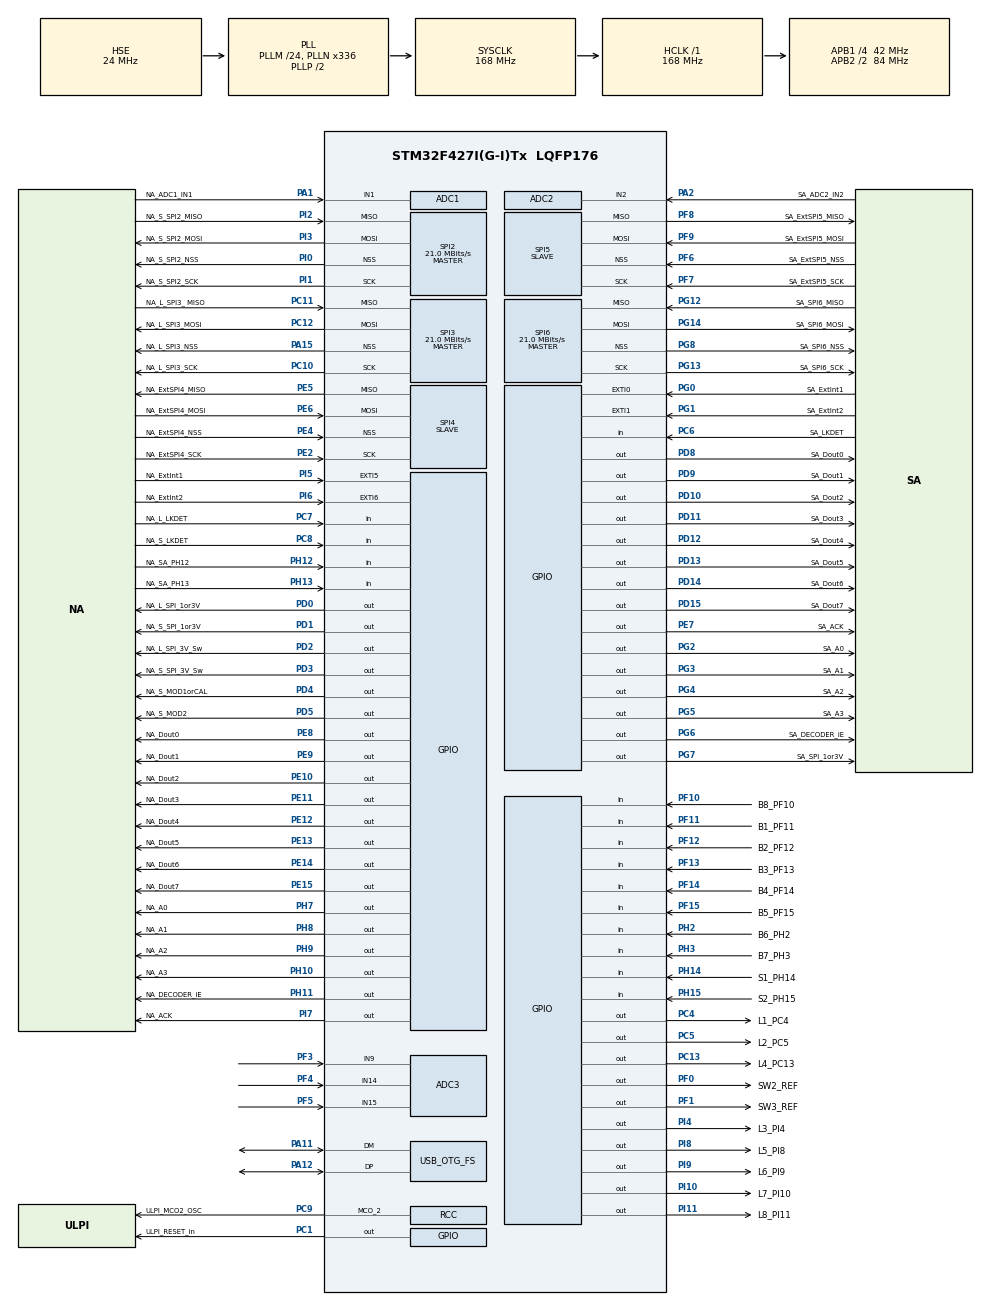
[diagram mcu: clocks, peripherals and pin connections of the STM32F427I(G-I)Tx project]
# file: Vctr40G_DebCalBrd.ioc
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ADC1.Channel-0\#ChannelRegularConversion=ADC_CHANNEL_1
ADC1.ClockPrescaler=ADC_CLOCK_SYNC_PCLK_DIV4
ADC1.NbrOfConversionFlag=1
ADC1.Rank-0\#ChannelRegularConversion=1
ADC1.SamplingTime-0\#ChannelRegularConversion=ADC_SAMPLETIME_3CYCLES
ADC1.master=1
ADC2.Channel-0\#ChannelRegularConversion=ADC_CHANNEL_2
ADC2.ClockPrescaler=ADC_CLOCK_SYNC_PCLK_DIV4
ADC2.NbrOfConversionFlag=1
ADC2.Rank-0\#ChannelRegularConversion=1
ADC2.SamplingTime-0\#ChannelRegularConversion=ADC_SAMPLETIME_3CYCLES
ADC3.Channel-0\#ChannelRegularConversion=ADC_CHANNEL_9
ADC3.ClockPrescaler=ADC_CLOCK_SYNC_PCLK_DIV4
ADC3.NbrOfConversionFlag=1
ADC3.Rank-0\#ChannelRegularConversion=1
ADC3.SamplingTime-0\#ChannelRegularConversion=ADC_SAMPLETIME_3CYCLES
Mcu.Family=STM32F4
Mcu.Name=STM32F427I(G-I)Tx
Mcu.Package=LQFP176
NVIC.EXTI0_IRQn=true\:0\:0\:false\:false\:true\:true\:true\:true
NVIC.EXTI1_IRQn=true\:0\:0\:false\:false\:true\:true\:true\:true
NVIC.EXTI9_5_IRQn=true\:0\:0\:false\:false\:true\:true\:true\:true
NVIC.OTG_FS_IRQn=true\:0\:0\:false\:false\:true\:false\:true\:true
NVIC.PriorityGroup=NVIC_PRIORITYGROUP_4
NVIC.SPI2_IRQn=true\:0\:0\:false\:false\:true\:true\:true\:true
NVIC.SPI3_IRQn=true\:0\:0\:false\:false\:true\:true\:true\:true
NVIC.SPI4_IRQn=true\:0\:0\:false\:false\:true\:true\:true\:true
NVIC.SPI5_IRQn=true\:0\:0\:false\:false\:true\:true\:true\:true
NVIC.SPI6_IRQn=true\:0\:0\:false\:false\:true\:true\:true\:true
NVIC.TIM1_UP_TIM10_IRQn=true\:0\:0\:false\:false\:true\:true\:true\:true
PA0/WKUP.Mode=SYS_WakeUp0
PA0/WKUP.Signal=SYS_WKUP
PA1.GPIO_Label=NA_ADC1_IN1
PA1.Signal=ADCx_IN1
PA11.Mode=Device_Only
PA11.Signal=USB_OTG_FS_DM
PA12.Mode=Device_Only
PA12.Signal=USB_OTG_FS_DP
PA13.Mode=Serial_Wire
PA13.Signal=SYS_JTMS-SWDIO
PA14.Mode=Serial_Wire
PA14.Signal=SYS_JTCK-SWCLK
PA15.GPIO_Label=NA_L_SPI3_NSS
PA15.Mode=NSS_Signal_Hard_Output
PA15.Signal=SPI3_NSS
PA2.GPIO_Label=SA_ADC2_IN2
PA2.Signal=ADCx_IN2
PA3.Signal=USB_OTG_HS_ULPI_D0
PA5.Signal=USB_OTG_HS_ULPI_CK
PB0.Signal=USB_OTG_HS_ULPI_D1
PB1.Signal=USB_OTG_HS_ULPI_D2
PB10.Signal=USB_OTG_HS_ULPI_D3
PB11.Signal=USB_OTG_HS_ULPI_D4
PB12.Signal=USB_OTG_HS_ULPI_D5
PB13.Signal=USB_OTG_HS_ULPI_D6
PB3.Signal=SYS_JTDO-SWO
PB4.Signal=SYS_JTRST
PB5.Signal=USB_OTG_HS_ULPI_D7
PC0.Signal=USB_OTG_HS_ULPI_STP
PC1.GPIO_Label=ULPI_RESET_in
PC1.Signal=GPIO_Output
PC10.GPIO_Label=NA_L_SPI3_SCK
PC10.Mode=Full_Duplex_Master
PC10.Signal=SPI3_SCK
PC11.GPIO_Label=NA_L_SPI3_ MISO
PC11.Mode=Full_Duplex_Master
PC11.Signal=SPI3_MISO
PC12.GPIO_Label=NA_L_SPI3_MOSI
PC12.Mode=Full_Duplex_Master
PC12.Signal=SPI3_MOSI
PC13.GPIO_Label=L4_PC13
PC13.Signal=GPIO_Output
PC14/OSC32_IN.Mode=LSE-External-Oscillator
PC14/OSC32_IN.Signal=RCC_OSC32_IN
PC15/OSC32_OUT.Mode=LSE-External-Oscillator
PC15/OSC32_OUT.Signal=RCC_OSC32_OUT
PC2.Signal=USB_OTG_HS_ULPI_DIR
PC3.Signal=USB_OTG_HS_ULPI_NXT
PC4.GPIO_Label=L1_PC4
PC4.Signal=GPIO_Output
PC5.GPIO_Label=L2_PC5
PC5.Signal=GPIO_Output
PC6.GPIO_Label=SA_LKDET
PC6.Signal=GPIO_Input
PC7.GPIO_Label=NA_L_LKDET
PC7.Signal=GPIO_Input
PC8.GPIO_Label=NA_S_LKDET
PC8.Signal=GPIO_Input
PC9.GPIO_Label=ULPI_MCO2_OSC
PC9.GPIO_Speed=GPIO_SPEED_FREQ_VERY_HIGH
PC9.Mode=Clock-out-2
PC9.Signal=RCC_MCO_2
PD0.GPIO_Label=NA_L_SPI_1or3V
PD0.GPIO_Speed=GPIO_SPEED_FREQ_VERY_HIGH
PD0.Signal=GPIO_Output
PD1.GPIO_Label=NA_S_SPI_1or3V
PD1.GPIO_Speed=GPIO_SPEED_FREQ_VERY_HIGH
PD1.Signal=GPIO_Output
PD10.GPIO_Label=SA_Dout2
PD10.GPIO_Speed=GPIO_SPEED_FREQ_VERY_HIGH
PD10.Signal=GPIO_Output
PD11.GPIO_Label=SA_Dout3
PD11.GPIO_Speed=GPIO_SPEED_FREQ_VERY_HIGH
PD11.Signal=GPIO_Output
PD12.GPIO_Label=SA_Dout4
PD12.GPIO_Speed=GPIO_SPEED_FREQ_VERY_HIGH
PD12.Signal=GPIO_Output
PD13.GPIO_Label=SA_Dout5
PD13.GPIO_Speed=GPIO_SPEED_FREQ_VERY_HIGH
PD13.Signal=GPIO_Output
PD14.GPIO_Label=SA_Dout6
PD14.GPIO_Speed=GPIO_SPEED_FREQ_VERY_HIGH
PD14.Signal=GPIO_Output
PD15.GPIO_Label=SA_Dout7
PD15.GPIO_Speed=GPIO_SPEED_FREQ_VERY_HIGH
PD15.Signal=GPIO_Output
PD2.GPIO_Label=NA_L_SPI_3V_Sw
PD2.GPIO_Speed=GPIO_SPEED_FREQ_VERY_HIGH
PD2.Signal=GPIO_Output
PD3.GPIO_Label=NA_S_SPI_3V_Sw
PD3.GPIO_Speed=GPIO_SPEED_FREQ_VERY_HIGH
PD3.Signal=GPIO_Output
PD4.GPIO_Label=NA_S_MOD1orCAL
PD4.GPIO_Speed=GPIO_SPEED_FREQ_VERY_HIGH
PD4.Signal=GPIO_Output
PD5.GPIO_Label=NA_S_MOD2
PD5.GPIO_Speed=GPIO_SPEED_FREQ_VERY_HIGH
PD5.Signal=GPIO_Output
PD8.GPIO_Label=SA_Dout0
PD8.GPIO_Speed=GPIO_SPEED_FREQ_VERY_HIGH
PD8.Signal=GPIO_Output
PD9.GPIO_Label=SA_Dout1
PD9.GPIO_Speed=GPIO_SPEED_FREQ_VERY_HIGH
PD9.Signal=GPIO_Output
PE0.GPIO_Label=MC_RX
PE0.Signal=UART8_RX
PE1.GPIO_Label=MC_TX
PE1.Signal=UART8_TX
PE10.GPIO_Label=NA_Dout2
PE10.GPIO_Speed=GPIO_SPEED_FREQ_VERY_HIGH
PE10.Signal=GPIO_Output
PE11.GPIO_Label=NA_Dout3
PE11.GPIO_Speed=GPIO_SPEED_FREQ_VERY_HIGH
PE11.Signal=GPIO_Output
PE12.GPIO_Label=NA_Dout4
PE12.GPIO_Speed=GPIO_SPEED_FREQ_VERY_HIGH
PE12.Signal=GPIO_Output
PE13.GPIO_Label=NA_Dout5
PE13.GPIO_Speed=GPIO_SPEED_FREQ_VERY_HIGH
PE13.Signal=GPIO_Output
PE14.GPIO_Label=NA_Dout6
PE14.GPIO_Speed=GPIO_SPEED_FREQ_VERY_HIGH
PE14.Signal=GPIO_Output
PE15.GPIO_Label=NA_Dout7
PE15.GPIO_Speed=GPIO_SPEED_FREQ_VERY_HIGH
PE15.Signal=GPIO_Output
PE2.GPIO_Label=NA_ExtSPI4_SCK
PE2.Mode=Full_Duplex_Slave
PE2.Signal=SPI4_SCK
PE4.GPIO_Label=NA_ExtSPI4_NSS
PE4.Mode=NSS_Signal_Hard_Input
PE4.Signal=SPI4_NSS
PE5.GPIO_Label=NA_ExtSPI4_MISO
PE5.Mode=Full_Duplex_Slave
PE5.Signal=SPI4_MISO
PE6.GPIO_Label=NA_ExtSPI4_MOSI
PE6.Mode=Full_Duplex_Slave
PE6.Signal=SPI4_MOSI
PE7.GPIO_Label=SA_ACK
PE7.GPIO_Speed=GPIO_SPEED_FREQ_VERY_HIGH
PE7.Signal=GPIO_Output
PE8.GPIO_Label=NA_Dout0
PE8.GPIO_Speed=GPIO_SPEED_FREQ_VERY_HIGH
PE8.Signal=GPIO_Output
PE9.GPIO_Label=NA_Dout1
PE9.GPIO_Speed=GPIO_SPEED_FREQ_VERY_HIGH
PE9.Signal=GPIO_Output
PF0.GPIO_Label=SW2_REF
PF0.GPIO_Speed=GPIO_SPEED_FREQ_VERY_HIGH
PF0.Signal=GPIO_Output
PF1.GPIO_Label=SW3_REF
PF1.GPIO_Speed=GPIO_SPEED_FREQ_VERY_HIGH
PF1.Signal=GPIO_Output
PF10.GPIO_Label=B8_PF10
PF10.Signal=GPIO_Input
PF11.GPIO_Label=B1_PF11
PF11.Signal=GPIO_Input
PF12.GPIO_Label=B2_PF12
PF12.Signal=GPIO_Input
PF13.GPIO_Label=B3_PF13
PF13.Signal=GPIO_Input
PF14.GPIO_Label=B4_PF14
PF14.Signal=GPIO_Input
PF15.GPIO_Label=B5_PF15
PF15.Signal=GPIO_Input
PF3.Mode=IN9
PF3.Signal=ADC3_IN9
PF4.Mode=IN14
PF4.Signal=ADC3_IN14
PF5.Mode=IN15
PF5.Signal=ADC3_IN15
PF6.GPIO_Label=SA_ExtSPI5_NSS
PF6.Mode=NSS_Signal_Hard_Input
PF6.Signal=SPI5_NSS
PF7.GPIO_Label=SA_ExtSPI5_SCK
PF7.Mode=Full_Duplex_Slave
PF7.Signal=SPI5_SCK
PF8.GPIO_Label=SA_ExtSPI5_MISO
PF8.Mode=Full_Duplex_Slave
PF8.Signal=SPI5_MISO
PF9.GPIO_Label=SA_ExtSPI5_MOSI
PF9.Mode=Full_Duplex_Slave
PF9.Signal=SPI5_MOSI
PG0.GPIO_Label=SA_ExtInt1
PG0.Signal=GPXTI0
PG1.GPIO_Label=SA_ExtInt2
PG1.Signal=GPXTI1
PG12.GPIO_Label=SA_SPI6_MISO
PG12.Mode=Full_Duplex_Master
PG12.Signal=SPI6_MISO
PG13.GPIO_Label=SA_SPI6_SCK
PG13.Mode=Full_Duplex_Master
PG13.Signal=SPI6_SCK
PG14.GPIO_Label=SA_SPI6_MOSI
PG14.Mode=Full_Duplex_Master
PG14.Signal=SPI6_MOSI
PG2.GPIO_Label=SA_A0
PG2.GPIO_Speed=GPIO_SPEED_FREQ_VERY_HIGH
PG2.Signal=GPIO_Output
PG3.GPIO_Label=SA_A1
PG3.GPIO_Speed=GPIO_SPEED_FREQ_VERY_HIGH
PG3.Signal=GPIO_Output
PG4.GPIO_Label=SA_A2
PG4.GPIO_Speed=GPIO_SPEED_FREQ_VERY_HIGH
PG4.Signal=GPIO_Output
PG5.GPIO_Label=SA_A3
PG5.GPIO_Speed=GPIO_SPEED_FREQ_VERY_HIGH
PG5.Signal=GPIO_Output
PG6.GPIO_Label=SA_DECODER_iE
PG6.GPIO_Speed=GPIO_SPEED_FREQ_VERY_HIGH
PG6.Signal=GPIO_Output
PG7.GPIO_Label=SA_SPI_1or3V
PG7.GPIO_Speed=GPIO_SPEED_FREQ_VERY_HIGH
PG7.Signal=GPIO_Output
PG8.GPIO_Label=SA_SPI6_NSS
PG8.Mode=NSS_Signal_Hard_Output
PG8.Signal=SPI6_NSS
PH0/OSC_IN.Mode=HSE-External-Oscillator
PH0/OSC_IN.Signal=RCC_OSC_IN
PH1/OSC_OUT.Mode=HSE-External-Oscillator
PH1/OSC_OUT.Signal=RCC_OSC_OUT
PH10.GPIO_Label=NA_A3
PH10.GPIO_Speed=GPIO_SPEED_FREQ_VERY_HIGH
PH10.Signal=GPIO_Output
PH11.GPIO_Label=NA_DECODER_iE
PH11.GPIO_Speed=GPIO_SPEED_FREQ_VERY_HIGH
PH11.Signal=GPIO_Output
PH12.GPIO_Label=NA_SA_PH12
PH12.Signal=GPIO_Input
PH13.GPIO_Label=NA_SA_PH13
PH13.Signal=GPIO_Input
PH14.GPIO_Label=S1_PH14
PH14.Signal=GPIO_Input
PH15.GPIO_Label=S2_PH15
PH15.Signal=GPIO_Input
PH2.GPIO_Label=B6_PH2
PH2.Signal=GPIO_Input
PH3.GPIO_Label=B7_PH3
PH3.Signal=GPIO_Input
PH4.GPIO_Label=E_I2C2_SCL
PH4.Signal=I2C2_SCL
PH5.GPIO_Label=E_I2C2_SDA
PH5.Signal=I2C2_SDA
PH7.GPIO_Label=NA_A0
PH7.GPIO_Speed=GPIO_SPEED_FREQ_VERY_HIGH
PH7.Signal=GPIO_Output
PH8.GPIO_Label=NA_A1
PH8.GPIO_Speed=GPIO_SPEED_FREQ_VERY_HIGH
PH8.Signal=GPIO_Output
PH9.GPIO_Label=NA_A2
PH9.GPIO_Speed=GPIO_SPEED_FREQ_VERY_HIGH
PH9.Signal=GPIO_Output
PI0.GPIO_Label=NA_S_SPI2_NSS
PI0.Mode=NSS_Signal_Hard_Output
PI0.Signal=SPI2_NSS
PI1.GPIO_Label=NA_S_SPI2_SCK
PI1.Mode=Full_Duplex_Master
PI1.Signal=SPI2_SCK
PI10.GPIO_Label=L7_PI10
PI10.Signal=GPIO_Output
PI11.GPIO_Label=L8_PI11
PI11.Signal=GPIO_Output
PI2.GPIO_Label=NA_S_SPI2_MISO
PI2.Mode=Full_Duplex_Master
PI2.Signal=SPI2_MISO
PI3.GPIO_Label=NA_S_SPI2_MOSI
PI3.Mode=Full_Duplex_Master
PI3.Signal=SPI2_MOSI
PI4.GPIO_Label=L3_PI4
PI4.Signal=GPIO_Output
PI5.GPIO_Label=NA_ExtInt1
PI5.Signal=GPXTI5
PI6.GPIO_Label=NA_ExtInt2
PI6.Signal=GPXTI6
PI7.GPIO_Label=NA_ACK
PI7.GPIO_Speed=GPIO_SPEED_FREQ_VERY_HIGH
PI7.Signal=GPIO_Output
PI8.GPIO_Label=L5_PI8
PI8.Signal=GPIO_Output
PI9.GPIO_Label=L6_PI9
PI9.Signal=GPIO_Output
ProjectManager.HeapSize=0x200
ProjectManager.StackSize=0x400
ProjectManager.TargetToolchain=STM32CubeIDE
RCC.48MHZClocksFreq_Value=48000000
RCC.AHBFreq_Value=168000000
RCC.APB1CLKDivider=RCC_HCLK_DIV4
RCC.APB1Freq_Value=42000000
RCC.APB1TimFreq_Value=84000000
RCC.APB2CLKDivider=RCC_HCLK_DIV2
RCC.APB2Freq_Value=84000000
RCC.APB2TimFreq_Value=168000000
RCC.CortexFreq_Value=168000000
RCC.HCLKFreq_Value=168000000
RCC.HSE_VALUE=24000000
RCC.HSI_VALUE=16000000
RCC.PLLM=24
RCC.PLLN=336
RCC.PLLQ=7
RCC.RCC_MCO2Source=RCC_MCO2SOURCE_HSE
RCC.SYSCLKFreq_VALUE=168000000
RCC.SYSCLKSource=RCC_SYSCLKSOURCE_PLLCLK
RCC.VCOOutputFreq_Value=336000000
SH.ADCx_IN1.0=ADC1_IN1,IN1
SH.ADCx_IN2.0=ADC2_IN2,IN2
SPI2.BaudRatePrescaler=SPI_BAUDRATEPRESCALER_2
SPI2.CalculateBaudRate=21.0 MBits/s
SPI2.Direction=SPI_DIRECTION_2LINES
SPI2.Mode=SPI_MODE_MASTER
SPI2.VirtualNSS=VM_NSSHARD
SPI2.VirtualType=VM_MASTER
SPI3.BaudRatePrescaler=SPI_BAUDRATEPRESCALER_2
SPI3.CalculateBaudRate=21.0 MBits/s
SPI3.Direction=SPI_DIRECTION_2LINES
SPI3.Mode=SPI_MODE_MASTER
SPI3.VirtualNSS=VM_NSSHARD
SPI3.VirtualType=VM_MASTER
SPI4.Direction=SPI_DIRECTION_2LINES
SPI4.Mode=SPI_MODE_SLAVE
SPI4.VirtualNSS=VM_NSSHARD
SPI4.VirtualType=VM_SLAVE
SPI5.Direction=SPI_DIRECTION_2LINES
SPI5.Mode=SPI_MODE_SLAVE
SPI5.VirtualNSS=VM_NSSHARD
SPI5.VirtualType=VM_SLAVE
SPI6.BaudRatePrescaler=SPI_BAUDRATEPRESCALER_4
SPI6.CalculateBaudRate=21.0 MBits/s
SPI6.Direction=SPI_DIRECTION_2LINES
SPI6.Mode=SPI_MODE_MASTER
SPI6.VirtualNSS=VM_NSSHARD
SPI6.VirtualType=VM_MASTER
TIM10.Period=10
TIM10.Prescaler=16799
USB_DEVICE.CLASS_NAME_FS=CDC
USB_DEVICE.VirtualMode-CDC_FS=Cdc
USB_DEVICE.VirtualModeFS=Cdc_FS
USB_OTG_FS.VirtualMode=Device_Only
VP_TIM10_VS_ClockSourceINT.Mode=Enable_Timer
VP_USB_DEVICE_VS_USB_DEVICE_CDC_FS.Mode=CDC_FS
board=custom

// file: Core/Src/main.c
/* USER CODE BEGIN Header */
/**
  ******************************************************************************
  * @file           : main.c
  * @brief          : Main program body
  ******************************************************************************
  * @attention
  *
  * Copyright (c) 2026 STMicroelectronics.
  * All rights reserved.
  *
  * This software is licensed under terms that can be found in the LICENSE file
  * in the root directory of this software component.
  * If no LICENSE file comes with this software, it is provided AS-IS.
  *
  ******************************************************************************
  */
/** !!!     ZAMJATKI     !!!
 * 1). 	L1_PC4 connected to USB echo (usbd_cdc_if.c): OFF/ON - "0"/"1" CDC_Receive_FS
 * 		L1_PC4 blinks in while(1)
 * 2). Switch USB FS / USB HS is difficult in work
 *
 */

/* USER CODE END Header */
#include "main.h"
#include "usb_device.h"

/* USER CODE BEGIN Includes */
#include "button_led.h"
#include "command.h"
/* USER CODE END Includes */

ADC_HandleTypeDef hadc1;
ADC_HandleTypeDef hadc2;
ADC_HandleTypeDef hadc3;

SPI_HandleTypeDef hspi2;
SPI_HandleTypeDef hspi3;
SPI_HandleTypeDef hspi4;
SPI_HandleTypeDef hspi5;
SPI_HandleTypeDef hspi6;

TIM_HandleTypeDef htim10;

/* USER CODE BEGIN PV */
volatile uint8_t pending_cmd = 0;
volatile uint8_t objState_cmd = 0;
/* USER CODE END PV */

void SystemClock_Config(void);
static void MX_GPIO_Init(void);
static void MX_ADC1_Init(void);
static void MX_ADC2_Init(void);
static void MX_ADC3_Init(void);
static void MX_SPI2_Init(void);
static void MX_SPI3_Init(void);
static void MX_SPI4_Init(void);
static void MX_SPI5_Init(void);
static void MX_SPI6_Init(void);
static void MX_TIM10_Init(void);

int main(void)
{

  /* MCU Configuration--------------------------------------------------------*/

  /* Reset of all peripherals, Initializes the Flash interface and the Systick. */
  HAL_Init();

  /* Configure the system clock */
  SystemClock_Config();

  /* USER CODE BEGIN SysInit */
  // latch strobe = 1
  HAL_GPIO_WritePin(NA_LATCH_STROBE_Port, NA_LATCH_STROBE_Pin, GPIO_PIN_SET);
  HAL_GPIO_WritePin(SA_LATCH_STROBE_Port, SA_LATCH_STROBE_Pin, GPIO_PIN_SET);
  /* USER CODE END SysInit */

  /* Initialize all configured peripherals */
  MX_GPIO_Init();
  MX_ADC1_Init();
  MX_ADC2_Init();
  MX_ADC3_Init();
  MX_SPI2_Init();
  MX_SPI3_Init();
  MX_SPI4_Init();
  MX_SPI5_Init();
  MX_SPI6_Init();
  MX_USB_DEVICE_Init();
  MX_TIM10_Init();
  /* USER CODE BEGIN 2 */
  HAL_TIM_Base_Start_IT(&htim10);
  /* USER CODE END 2 */

  /* Infinite loop */
  /* USER CODE BEGIN WHILE */
  while (1) {
      //	  // blink of work ability
      //	  HAL_GPIO_TogglePin(L1_PortC, L1_PC4_Pin);
      //	  HAL_Delay(250);
      //	  HAL_GPIO_TogglePin(L1_PortC, L1_PC4_Pin);

      // === command execution
      if (pending_cmd) {
          ProcessCommandTask(pending_cmd, objState_cmd);
      }

      //  === continuous process dispatch
      if (processFlags &= PROC_PULSEMOD) {
          PulseMOD_Process();
          PulseMOD_Process();
          PulseMOD_Process();
          PulseMOD_Process();
      }
      if (processFlags & PROC_NA_DYNAMIC_TEST) {
          NATest_Process();
      }
      if (processFlags & PROC_SA_DYNAMIC_TEST) {
          SATest_Process();
      }
      // future processes:
      // if (processFlags & PROC_1) { Process1(); }
      // if (processFlags & PROC_2) { Process2(); }

      /* USER CODE END WHILE */

  }
}

void SystemClock_Config(void)
{
  RCC_OscInitTypeDef RCC_OscInitStruct = {0};
  RCC_ClkInitTypeDef RCC_ClkInitStruct = {0};

  /** Configure the main internal regulator output voltage
  */
  __HAL_RCC_PWR_CLK_ENABLE();
  __HAL_PWR_VOLTAGESCALING_CONFIG(PWR_REGULATOR_VOLTAGE_SCALE1);

  /** Initializes the RCC Oscillators according to the specified parameters
  * in the RCC_OscInitTypeDef structure.
  */
  RCC_OscInitStruct.OscillatorType = RCC_OSCILLATORTYPE_HSE;
  RCC_OscInitStruct.HSEState = RCC_HSE_ON;
  RCC_OscInitStruct.PLL.PLLState = RCC_PLL_ON;
  RCC_OscInitStruct.PLL.PLLSource = RCC_PLLSOURCE_HSE;
  RCC_OscInitStruct.PLL.PLLM = 24;
  RCC_OscInitStruct.PLL.PLLN = 336;
  RCC_OscInitStruct.PLL.PLLP = RCC_PLLP_DIV2;
  RCC_OscInitStruct.PLL.PLLQ = 7;
  if (HAL_RCC_OscConfig(&RCC_OscInitStruct) != HAL_OK)
  {
    Error_Handler();
  }

  /** Initializes the CPU, AHB and APB buses clocks
  */
  RCC_ClkInitStruct.ClockType = RCC_CLOCKTYPE_HCLK|RCC_CLOCKTYPE_SYSCLK
                              |RCC_CLOCKTYPE_PCLK1|RCC_CLOCKTYPE_PCLK2;
  RCC_ClkInitStruct.SYSCLKSource = RCC_SYSCLKSOURCE_PLLCLK;
  RCC_ClkInitStruct.AHBCLKDivider = RCC_SYSCLK_DIV1;
  RCC_ClkInitStruct.APB1CLKDivider = RCC_HCLK_DIV4;
  RCC_ClkInitStruct.APB2CLKDivider = RCC_HCLK_DIV2;

  if (HAL_RCC_ClockConfig(&RCC_ClkInitStruct, FLASH_LATENCY_5) != HAL_OK)
  {
    Error_Handler();
  }
  HAL_RCC_MCOConfig(RCC_MCO2, RCC_MCO2SOURCE_HSE, RCC_MCODIV_1);
}

static void MX_ADC1_Init(void)
{

  ADC_ChannelConfTypeDef sConfig = {0};

  /** Configure the global features of the ADC (Clock, Resolution, Data Alignment and number of conversion)
  */
  hadc1.Instance = ADC1;
  hadc1.Init.ClockPrescaler = ADC_CLOCK_SYNC_PCLK_DIV4;
  hadc1.Init.Resolution = ADC_RESOLUTION_12B;
  hadc1.Init.ScanConvMode = DISABLE;
  hadc1.Init.ContinuousConvMode = DISABLE;
  hadc1.Init.DiscontinuousConvMode = DISABLE;
  hadc1.Init.ExternalTrigConvEdge = ADC_EXTERNALTRIGCONVEDGE_NONE;
  hadc1.Init.ExternalTrigConv = ADC_SOFTWARE_START;
  hadc1.Init.DataAlign = ADC_DATAALIGN_RIGHT;
  hadc1.Init.NbrOfConversion = 1;
  hadc1.Init.DMAContinuousRequests = DISABLE;
  hadc1.Init.EOCSelection = ADC_EOC_SINGLE_CONV;
  if (HAL_ADC_Init(&hadc1) != HAL_OK)
  {
    Error_Handler();
  }

  /** Configure for the selected ADC regular channel its corresponding rank in the sequencer and its sample time.
  */
  sConfig.Channel = ADC_CHANNEL_1;
  sConfig.Rank = 1;
  sConfig.SamplingTime = ADC_SAMPLETIME_3CYCLES;
  if (HAL_ADC_ConfigChannel(&hadc1, &sConfig) != HAL_OK)
  {
    Error_Handler();
  }

}

static void MX_ADC2_Init(void)
{

  ADC_ChannelConfTypeDef sConfig = {0};

  /** Configure the global features of the ADC (Clock, Resolution, Data Alignment and number of conversion)
  */
  hadc2.Instance = ADC2;
  hadc2.Init.ClockPrescaler = ADC_CLOCK_SYNC_PCLK_DIV4;
  hadc2.Init.Resolution = ADC_RESOLUTION_12B;
  hadc2.Init.ScanConvMode = DISABLE;
  hadc2.Init.ContinuousConvMode = DISABLE;
  hadc2.Init.DiscontinuousConvMode = DISABLE;
  hadc2.Init.ExternalTrigConvEdge = ADC_EXTERNALTRIGCONVEDGE_NONE;
  hadc2.Init.ExternalTrigConv = ADC_SOFTWARE_START;
  hadc2.Init.DataAlign = ADC_DATAALIGN_RIGHT;
  hadc2.Init.NbrOfConversion = 1;
  hadc2.Init.DMAContinuousRequests = DISABLE;
  hadc2.Init.EOCSelection = ADC_EOC_SINGLE_CONV;
  if (HAL_ADC_Init(&hadc2) != HAL_OK)
  {
    Error_Handler();
  }

  /** Configure for the selected ADC regular channel its corresponding rank in the sequencer and its sample time.
  */
  sConfig.Channel = ADC_CHANNEL_2;
  sConfig.Rank = 1;
  sConfig.SamplingTime = ADC_SAMPLETIME_3CYCLES;
  if (HAL_ADC_ConfigChannel(&hadc2, &sConfig) != HAL_OK)
  {
    Error_Handler();
  }

}

static void MX_ADC3_Init(void)
{

  ADC_ChannelConfTypeDef sConfig = {0};

  /** Configure the global features of the ADC (Clock, Resolution, Data Alignment and number of conversion)
  */
  hadc3.Instance = ADC3;
  hadc3.Init.ClockPrescaler = ADC_CLOCK_SYNC_PCLK_DIV4;
  hadc3.Init.Resolution = ADC_RESOLUTION_12B;
  hadc3.Init.ScanConvMode = DISABLE;
  hadc3.Init.ContinuousConvMode = DISABLE;
  hadc3.Init.DiscontinuousConvMode = DISABLE;
  hadc3.Init.ExternalTrigConvEdge = ADC_EXTERNALTRIGCONVEDGE_NONE;
  hadc3.Init.ExternalTrigConv = ADC_SOFTWARE_START;
  hadc3.Init.DataAlign = ADC_DATAALIGN_RIGHT;
  hadc3.Init.NbrOfConversion = 1;
  hadc3.Init.DMAContinuousRequests = DISABLE;
  hadc3.Init.EOCSelection = ADC_EOC_SINGLE_CONV;
  if (HAL_ADC_Init(&hadc3) != HAL_OK)
  {
    Error_Handler();
  }

  /** Configure for the selected ADC regular channel its corresponding rank in the sequencer and its sample time.
  */
  sConfig.Channel = ADC_CHANNEL_9;
  sConfig.Rank = 1;
  sConfig.SamplingTime = ADC_SAMPLETIME_3CYCLES;
  if (HAL_ADC_ConfigChannel(&hadc3, &sConfig) != HAL_OK)
  {
    Error_Handler();
  }

}

static void MX_SPI2_Init(void)
{

  /* SPI2 parameter configuration*/
  hspi2.Instance = SPI2;
  hspi2.Init.Mode = SPI_MODE_MASTER;
  hspi2.Init.Direction = SPI_DIRECTION_2LINES;
  hspi2.Init.DataSize = SPI_DATASIZE_8BIT;
  hspi2.Init.CLKPolarity = SPI_POLARITY_LOW;
  hspi2.Init.CLKPhase = SPI_PHASE_1EDGE;
  hspi2.Init.NSS = SPI_NSS_HARD_OUTPUT;
  hspi2.Init.BaudRatePrescaler = SPI_BAUDRATEPRESCALER_2;
  hspi2.Init.FirstBit = SPI_FIRSTBIT_MSB;
  hspi2.Init.TIMode = SPI_TIMODE_DISABLE;
  hspi2.Init.CRCCalculation = SPI_CRCCALCULATION_DISABLE;
  hspi2.Init.CRCPolynomial = 10;
  if (HAL_SPI_Init(&hspi2) != HAL_OK)
  {
    Error_Handler();
  }

}

static void MX_SPI3_Init(void)
{

  /* SPI3 parameter configuration*/
  hspi3.Instance = SPI3;
  hspi3.Init.Mode = SPI_MODE_MASTER;
  hspi3.Init.Direction = SPI_DIRECTION_2LINES;
  hspi3.Init.DataSize = SPI_DATASIZE_8BIT;
  hspi3.Init.CLKPolarity = SPI_POLARITY_LOW;
  hspi3.Init.CLKPhase = SPI_PHASE_1EDGE;
  hspi3.Init.NSS = SPI_NSS_HARD_OUTPUT;
  hspi3.Init.BaudRatePrescaler = SPI_BAUDRATEPRESCALER_2;
  hspi3.Init.FirstBit = SPI_FIRSTBIT_MSB;
  hspi3.Init.TIMode = SPI_TIMODE_DISABLE;
  hspi3.Init.CRCCalculation = SPI_CRCCALCULATION_DISABLE;
  hspi3.Init.CRCPolynomial = 10;
  if (HAL_SPI_Init(&hspi3) != HAL_OK)
  {
    Error_Handler();
  }

}

static void MX_SPI4_Init(void)
{

  /* SPI4 parameter configuration*/
  hspi4.Instance = SPI4;
  hspi4.Init.Mode = SPI_MODE_SLAVE;
  hspi4.Init.Direction = SPI_DIRECTION_2LINES;
  hspi4.Init.DataSize = SPI_DATASIZE_8BIT;
  hspi4.Init.CLKPolarity = SPI_POLARITY_LOW;
  hspi4.Init.CLKPhase = SPI_PHASE_1EDGE;
  hspi4.Init.NSS = SPI_NSS_HARD_INPUT;
  hspi4.Init.FirstBit = SPI_FIRSTBIT_MSB;
  hspi4.Init.TIMode = SPI_TIMODE_DISABLE;
  hspi4.Init.CRCCalculation = SPI_CRCCALCULATION_DISABLE;
  hspi4.Init.CRCPolynomial = 10;
  if (HAL_SPI_Init(&hspi4) != HAL_OK)
  {
    Error_Handler();
  }

}

static void MX_SPI5_Init(void)
{

  /* SPI5 parameter configuration*/
  hspi5.Instance = SPI5;
  hspi5.Init.Mode = SPI_MODE_SLAVE;
  hspi5.Init.Direction = SPI_DIRECTION_2LINES;
  hspi5.Init.DataSize = SPI_DATASIZE_8BIT;
  hspi5.Init.CLKPolarity = SPI_POLARITY_LOW;
  hspi5.Init.CLKPhase = SPI_PHASE_1EDGE;
  hspi5.Init.NSS = SPI_NSS_HARD_INPUT;
  hspi5.Init.FirstBit = SPI_FIRSTBIT_MSB;
  hspi5.Init.TIMode = SPI_TIMODE_DISABLE;
  hspi5.Init.CRCCalculation = SPI_CRCCALCULATION_DISABLE;
  hspi5.Init.CRCPolynomial = 10;
  if (HAL_SPI_Init(&hspi5) != HAL_OK)
  {
    Error_Handler();
  }

}

static void MX_SPI6_Init(void)
{

  /* SPI6 parameter configuration*/
  hspi6.Instance = SPI6;
  hspi6.Init.Mode = SPI_MODE_MASTER;
  hspi6.Init.Direction = SPI_DIRECTION_2LINES;
  hspi6.Init.DataSize = SPI_DATASIZE_8BIT;
  hspi6.Init.CLKPolarity = SPI_POLARITY_LOW;
  hspi6.Init.CLKPhase = SPI_PHASE_1EDGE;
  hspi6.Init.NSS = SPI_NSS_HARD_OUTPUT;
  hspi6.Init.BaudRatePrescaler = SPI_BAUDRATEPRESCALER_4;
  hspi6.Init.FirstBit = SPI_FIRSTBIT_MSB;
  hspi6.Init.TIMode = SPI_TIMODE_DISABLE;
  hspi6.Init.CRCCalculation = SPI_CRCCALCULATION_DISABLE;
  hspi6.Init.CRCPolynomial = 10;
  if (HAL_SPI_Init(&hspi6) != HAL_OK)
  {
    Error_Handler();
  }

}

static void MX_TIM10_Init(void)
{

  htim10.Instance = TIM10;
  htim10.Init.Prescaler = 16799;
  htim10.Init.CounterMode = TIM_COUNTERMODE_UP;
  htim10.Init.Period = 10;
  htim10.Init.ClockDivision = TIM_CLOCKDIVISION_DIV1;
  htim10.Init.AutoReloadPreload = TIM_AUTORELOAD_PRELOAD_DISABLE;
  if (HAL_TIM_Base_Init(&htim10) != HAL_OK)
  {
    Error_Handler();
  }
  /* USER CODE BEGIN TIM10_Init 2 */
  HAL_NVIC_SetPriority(TIM1_UP_TIM10_IRQn, 0, 0);
  HAL_NVIC_EnableIRQ(TIM1_UP_TIM10_IRQn);
  /* USER CODE END TIM10_Init 2 */

}

static void MX_GPIO_Init(void)
{
  GPIO_InitTypeDef GPIO_InitStruct = {0};

  /* GPIO Ports Clock Enable */
  __HAL_RCC_GPIOE_CLK_ENABLE();
  __HAL_RCC_GPIOI_CLK_ENABLE();
  __HAL_RCC_GPIOC_CLK_ENABLE();
  __HAL_RCC_GPIOF_CLK_ENABLE();
  __HAL_RCC_GPIOH_CLK_ENABLE();
  __HAL_RCC_GPIOA_CLK_ENABLE();
  __HAL_RCC_GPIOB_CLK_ENABLE();
  __HAL_RCC_GPIOG_CLK_ENABLE();
  __HAL_RCC_GPIOD_CLK_ENABLE();

  /*Configure GPIO pin Output Level */
  HAL_GPIO_WritePin(GPIOI, L5_PI8_Pin|L6_PI9_Pin|L7_PI10_Pin|L8_PI11_Pin
                          |L3_PI4_Pin|NA_ACK_Pin, GPIO_PIN_RESET);

  /*Configure GPIO pin Output Level */
  HAL_GPIO_WritePin(GPIOC, L4_PC13_Pin|ULPI_RESET_in_Pin|L1_PC4_Pin|L2_PC5_Pin, GPIO_PIN_RESET);

  /*Configure GPIO pin Output Level */
  HAL_GPIO_WritePin(GPIOF, SW2_REF_Pin|SW3_REF_Pin, GPIO_PIN_RESET);

  /*Configure GPIO pin Output Level */
  HAL_GPIO_WritePin(GPIOE, SA_ACK_Pin|NA_Dout0_Pin|NA_Dout1_Pin|NA_Dout2_Pin
                          |NA_Dout3_Pin|NA_Dout4_Pin|NA_Dout5_Pin|NA_Dout6_Pin
                          |NA_Dout7_Pin, GPIO_PIN_RESET);

  /*Configure GPIO pin Output Level */
  HAL_GPIO_WritePin(GPIOH, NA_A0_Pin|NA_A1_Pin|NA_A2_Pin|NA_A3_Pin
                          |NA_DECODER_iE_Pin, GPIO_PIN_RESET);

  /*Configure GPIO pin Output Level */
  HAL_GPIO_WritePin(GPIOD, SA_Dout0_Pin|SA_Dout1_Pin|SA_Dout2_Pin|SA_Dout3_Pin
                          |SA_Dout4_Pin|SA_Dout5_Pin|SA_Dout6_Pin|SA_Dout7_Pin
                          |NA_L_SPI_1or3V_Pin|NA_S_SPI_1or3V_Pin|NA_L_SPI_3V_Sw_Pin|NA_S_SPI_3V_Sw_Pin
                          |NA_S_MOD1orCAL_Pin|NA_S_MOD2_Pin, GPIO_PIN_RESET);

  /*Configure GPIO pin Output Level */
  HAL_GPIO_WritePin(GPIOG, SA_A0_Pin|SA_A1_Pin|SA_A2_Pin|SA_A3_Pin
                          |SA_DECODER_iE_Pin|SA_SPI_1or3V_Pin, GPIO_PIN_RESET);

  /*Configure GPIO pins : L5_PI8_Pin L6_PI9_Pin L7_PI10_Pin L8_PI11_Pin
                           L3_PI4_Pin */
  GPIO_InitStruct.Pin = L5_PI8_Pin|L6_PI9_Pin|L7_PI10_Pin|L8_PI11_Pin
                          |L3_PI4_Pin;
  GPIO_InitStruct.Mode = GPIO_MODE_OUTPUT_PP;
  GPIO_InitStruct.Pull = GPIO_NOPULL;
  GPIO_InitStruct.Speed = GPIO_SPEED_FREQ_LOW;
  HAL_GPIO_Init(GPIOI, &GPIO_InitStruct);

  /*Configure GPIO pins : L4_PC13_Pin ULPI_RESET_in_Pin L1_PC4_Pin L2_PC5_Pin */
  GPIO_InitStruct.Pin = L4_PC13_Pin|ULPI_RESET_in_Pin|L1_PC4_Pin|L2_PC5_Pin;
  GPIO_InitStruct.Mode = GPIO_MODE_OUTPUT_PP;
  GPIO_InitStruct.Pull = GPIO_NOPULL;
  GPIO_InitStruct.Speed = GPIO_SPEED_FREQ_LOW;
  HAL_GPIO_Init(GPIOC, &GPIO_InitStruct);

  /*Configure GPIO pins : SW2_REF_Pin SW3_REF_Pin */
  GPIO_InitStruct.Pin = SW2_REF_Pin|SW3_REF_Pin;
  GPIO_InitStruct.Mode = GPIO_MODE_OUTPUT_PP;
  GPIO_InitStruct.Pull = GPIO_NOPULL;
  GPIO_InitStruct.Speed = GPIO_SPEED_FREQ_VERY_HIGH;
  HAL_GPIO_Init(GPIOF, &GPIO_InitStruct);

  /*Configure GPIO pins : B8_PF10_Pin B1_PF11_Pin B2_PF12_Pin B3_PF13_Pin
                           B4_PF14_Pin B5_PF15_Pin */
  GPIO_InitStruct.Pin = B8_PF10_Pin|B1_PF11_Pin|B2_PF12_Pin|B3_PF13_Pin
                          |B4_PF14_Pin|B5_PF15_Pin;
  GPIO_InitStruct.Mode = GPIO_MODE_INPUT;
  GPIO_InitStruct.Pull = GPIO_NOPULL;
  HAL_GPIO_Init(GPIOF, &GPIO_InitStruct);

  /*Configure GPIO pins : PC0 PC2 PC3 */
  GPIO_InitStruct.Pin = GPIO_PIN_0|GPIO_PIN_2|GPIO_PIN_3;
  GPIO_InitStruct.Mode = GPIO_MODE_AF_PP;
  GPIO_InitStruct.Pull = GPIO_NOPULL;
  GPIO_InitStruct.Speed = GPIO_SPEED_FREQ_VERY_HIGH;
  GPIO_InitStruct.Alternate = GPIO_AF10_OTG_HS;
  HAL_GPIO_Init(GPIOC, &GPIO_InitStruct);

  /*Configure GPIO pins : B6_PH2_Pin B7_PH3_Pin NA_SA_PH12_Pin NA_SA_PH13_Pin
                           S1_PH14_Pin S2_PH15_Pin */
  GPIO_InitStruct.Pin = B6_PH2_Pin|B7_PH3_Pin|NA_SA_PH12_Pin|NA_SA_PH13_Pin
                          |S1_PH14_Pin|S2_PH15_Pin;
  GPIO_InitStruct.Mode = GPIO_MODE_INPUT;
  GPIO_InitStruct.Pull = GPIO_NOPULL;
  HAL_GPIO_Init(GPIOH, &GPIO_InitStruct);

  /*Configure GPIO pins : E_I2C2_SCL_Pin E_I2C2_SDA_Pin */
  GPIO_InitStruct.Pin = E_I2C2_SCL_Pin|E_I2C2_SDA_Pin;
  GPIO_InitStruct.Mode = GPIO_MODE_AF_OD;
  GPIO_InitStruct.Pull = GPIO_NOPULL;
  GPIO_InitStruct.Speed = GPIO_SPEED_FREQ_VERY_HIGH;
  GPIO_InitStruct.Alternate = GPIO_AF4_I2C2;
  HAL_GPIO_Init(GPIOH, &GPIO_InitStruct);

  /*Configure GPIO pins : PA3 PA5 */
  GPIO_InitStruct.Pin = GPIO_PIN_3|GPIO_PIN_5;
  GPIO_InitStruct.Mode = GPIO_MODE_AF_PP;
  GPIO_InitStruct.Pull = GPIO_NOPULL;
  GPIO_InitStruct.Speed = GPIO_SPEED_FREQ_VERY_HIGH;
  GPIO_InitStruct.Alternate = GPIO_AF10_OTG_HS;
  HAL_GPIO_Init(GPIOA, &GPIO_InitStruct);

  /*Configure GPIO pins : PB0 PB1 PB10 PB11
                           PB12 PB13 PB5 */
  GPIO_InitStruct.Pin = GPIO_PIN_0|GPIO_PIN_1|GPIO_PIN_10|GPIO_PIN_11
                          |GPIO_PIN_12|GPIO_PIN_13|GPIO_PIN_5;
  GPIO_InitStruct.Mode = GPIO_MODE_AF_PP;
  GPIO_InitStruct.Pull = GPIO_NOPULL;
  GPIO_InitStruct.Speed = GPIO_SPEED_FREQ_VERY_HIGH;
  GPIO_InitStruct.Alternate = GPIO_AF10_OTG_HS;
  HAL_GPIO_Init(GPIOB, &GPIO_InitStruct);

  /*Configure GPIO pins : SA_ExtInt1_Pin SA_ExtInt2_Pin */
  GPIO_InitStruct.Pin = SA_ExtInt1_Pin|SA_ExtInt2_Pin;
  GPIO_InitStruct.Mode = GPIO_MODE_IT_RISING;
  GPIO_InitStruct.Pull = GPIO_NOPULL;
  HAL_GPIO_Init(GPIOG, &GPIO_InitStruct);

  /*Configure GPIO pins : SA_ACK_Pin NA_Dout0_Pin NA_Dout1_Pin NA_Dout2_Pin
                           NA_Dout3_Pin NA_Dout4_Pin NA_Dout5_Pin NA_Dout6_Pin
                           NA_Dout7_Pin */
  GPIO_InitStruct.Pin = SA_ACK_Pin|NA_Dout0_Pin|NA_Dout1_Pin|NA_Dout2_Pin
                          |NA_Dout3_Pin|NA_Dout4_Pin|NA_Dout5_Pin|NA_Dout6_Pin
                          |NA_Dout7_Pin;
  GPIO_InitStruct.Mode = GPIO_MODE_OUTPUT_PP;
  GPIO_InitStruct.Pull = GPIO_NOPULL;
  GPIO_InitStruct.Speed = GPIO_SPEED_FREQ_VERY_HIGH;
  HAL_GPIO_Init(GPIOE, &GPIO_InitStruct);

  /*Configure GPIO pins : NA_A0_Pin NA_A1_Pin NA_A2_Pin NA_A3_Pin
                           NA_DECODER_iE_Pin */
  GPIO_InitStruct.Pin = NA_A0_Pin|NA_A1_Pin|NA_A2_Pin|NA_A3_Pin
                          |NA_DECODER_iE_Pin;
  GPIO_InitStruct.Mode = GPIO_MODE_OUTPUT_PP;
  GPIO_InitStruct.Pull = GPIO_NOPULL;
  GPIO_InitStruct.Speed = GPIO_SPEED_FREQ_VERY_HIGH;
  HAL_GPIO_Init(GPIOH, &GPIO_InitStruct);

  /*Configure GPIO pins : SA_Dout0_Pin SA_Dout1_Pin SA_Dout2_Pin SA_Dout3_Pin
                           SA_Dout4_Pin SA_Dout5_Pin SA_Dout6_Pin SA_Dout7_Pin
                           NA_L_SPI_1or3V_Pin NA_S_SPI_1or3V_Pin NA_L_SPI_3V_Sw_Pin NA_S_SPI_3V_Sw_Pin
                           NA_S_MOD1orCAL_Pin NA_S_MOD2_Pin */
  GPIO_InitStruct.Pin = SA_Dout0_Pin|SA_Dout1_Pin|SA_Dout2_Pin|SA_Dout3_Pin
                          |SA_Dout4_Pin|SA_Dout5_Pin|SA_Dout6_Pin|SA_Dout7_Pin
                          |NA_L_SPI_1or3V_Pin|NA_S_SPI_1or3V_Pin|NA_L_SPI_3V_Sw_Pin|NA_S_SPI_3V_Sw_Pin
                          |NA_S_MOD1orCAL_Pin|NA_S_MOD2_Pin;
  GPIO_InitStruct.Mode = GPIO_MODE_OUTPUT_PP;
  GPIO_InitStruct.Pull = GPIO_NOPULL;
  GPIO_InitStruct.Speed = GPIO_SPEED_FREQ_VERY_HIGH;
  HAL_GPIO_Init(GPIOD, &GPIO_InitStruct);

  /*Configure GPIO pins : SA_A0_Pin SA_A1_Pin SA_A2_Pin SA_A3_Pin
                           SA_DECODER_iE_Pin SA_SPI_1or3V_Pin */
  GPIO_InitStruct.Pin = SA_A0_Pin|SA_A1_Pin|SA_A2_Pin|SA_A3_Pin
                          |SA_DECODER_iE_Pin|SA_SPI_1or3V_Pin;
  GPIO_InitStruct.Mode = GPIO_MODE_OUTPUT_PP;
  GPIO_InitStruct.Pull = GPIO_NOPULL;
  GPIO_InitStruct.Speed = GPIO_SPEED_FREQ_VERY_HIGH;
  HAL_GPIO_Init(GPIOG, &GPIO_InitStruct);

  /*Configure GPIO pins : SA_LKDET_Pin NA_L_LKDET_Pin NA_S_LKDET_Pin */
  GPIO_InitStruct.Pin = SA_LKDET_Pin|NA_L_LKDET_Pin|NA_S_LKDET_Pin;
  GPIO_InitStruct.Mode = GPIO_MODE_INPUT;
  GPIO_InitStruct.Pull = GPIO_NOPULL;
  HAL_GPIO_Init(GPIOC, &GPIO_InitStruct);

  /*Configure GPIO pin : ULPI_MCO2_OSC_Pin */
  GPIO_InitStruct.Pin = ULPI_MCO2_OSC_Pin;
  GPIO_InitStruct.Mode = GPIO_MODE_AF_PP;
  GPIO_InitStruct.Pull = GPIO_NOPULL;
  GPIO_InitStruct.Speed = GPIO_SPEED_FREQ_VERY_HIGH;
  GPIO_InitStruct.Alternate = GPIO_AF0_MCO;
  HAL_GPIO_Init(ULPI_MCO2_OSC_GPIO_Port, &GPIO_InitStruct);

  /*Configure GPIO pins : MC_RX_Pin MC_TX_Pin */
  GPIO_InitStruct.Pin = MC_RX_Pin|MC_TX_Pin;
  GPIO_InitStruct.Mode = GPIO_MODE_AF_PP;
  GPIO_InitStruct.Pull = GPIO_NOPULL;
  GPIO_InitStruct.Speed = GPIO_SPEED_FREQ_VERY_HIGH;
  GPIO_InitStruct.Alternate = GPIO_AF8_UART8;
  HAL_GPIO_Init(GPIOE, &GPIO_InitStruct);

  /*Configure GPIO pins : NA_ExtInt1_Pin NA_ExtInt2_Pin */
  GPIO_InitStruct.Pin = NA_ExtInt1_Pin|NA_ExtInt2_Pin;
  GPIO_InitStruct.Mode = GPIO_MODE_IT_RISING;
  GPIO_InitStruct.Pull = GPIO_NOPULL;
  HAL_GPIO_Init(GPIOI, &GPIO_InitStruct);

  /*Configure GPIO pin : NA_ACK_Pin */
  GPIO_InitStruct.Pin = NA_ACK_Pin;
  GPIO_InitStruct.Mode = GPIO_MODE_OUTPUT_PP;
  GPIO_InitStruct.Pull = GPIO_NOPULL;
  GPIO_InitStruct.Speed = GPIO_SPEED_FREQ_VERY_HIGH;
  HAL_GPIO_Init(NA_ACK_GPIO_Port, &GPIO_InitStruct);

  /* EXTI interrupt init*/
  HAL_NVIC_SetPriority(EXTI0_IRQn, 0, 0);
  HAL_NVIC_EnableIRQ(EXTI0_IRQn);

  HAL_NVIC_SetPriority(EXTI1_IRQn, 0, 0);
  HAL_NVIC_EnableIRQ(EXTI1_IRQn);

  HAL_NVIC_SetPriority(EXTI9_5_IRQn, 0, 0);
  HAL_NVIC_EnableIRQ(EXTI9_5_IRQn);

}

/* USER CODE BEGIN 4 */

void HAL_TIM_PeriodElapsedCallback(TIM_HandleTypeDef *htim) //************************
{
	// button inquiry
    if (htim->Instance == htim10.Instance) {
        for (uint8_t i = 0; i < BTN_NUM; i++) {
            GPIO_PinState currentState = HAL_GPIO_ReadPin(mcuPin[i].port, mcuPin[i].pin);
            if (currentState == mcuPin[i].lastState) {
                if (currentState == GPIO_PIN_SET) {
                    // the button is "1"
                    mcuPin[i].timer++;
                    if (mcuPin[i].timer == DEBOUNCE_TICKS) {
                        if (!mcuPin[i].is_held) {
                            mcuPin[i].is_held = BTN_PRESSED;
                        }
                    } else if (mcuPin[i].timer == HOLD_TICKS) {
                        mcuPin[i].is_held = BTN_HOLD;
                    } else if (mcuPin[i].timer == LONG_HOLD_TICKS) {
                        mcuPin[i].is_held = BTN_LONG_HOLD;
                    }
                }
            } else {
                mcuPin[i].lastState = currentState;
                // the button changed state
                if (mcuPin[i].is_held != BTN_NOT_PRESSED) {
                    if (mcuPin[i].is_held == BTN_PRESSED) {
                        // debounce time is over and the button was unpressed
                        if (mcuPin[i].callback)
                            mcuPin[i].callback(i, BTN_PRESSED);
                    } else if (mcuPin[i].is_held == BTN_HOLD) {
                        // the button was held and now is unpressed
                        if (mcuPin[i].callback)
                            mcuPin[i].callback(i, BTN_HOLD);
                    } else {
                        // the button was long held
                        if (mcuPin[i].callback) {
                            mcuPin[i].callback(i, BTN_LONG_HOLD);
                        }
                    }
                    mcuPin[i].lastState = 0;
                    mcuPin[i].timer     = 0;
                    mcuPin[i].is_held   = BTN_NOT_PRESSED;
                }
              }
            LED_Handler(i); // update LED state based on button state
        }
    }
}

void HAL_GPIO_EXTI_Callback(uint16_t GPIO_Pin) //************************
{
    //    if(GPIO_Pin == GPIO_PIN_0)
    //    {
    //        HAL_GPIO_TogglePin(GPIOD, GPIO_PIN_12);
    //    }
}

/* USER CODE END 4 */

void Error_Handler(void)
{
  __disable_irq();
  while (1)
  {
  }
}
